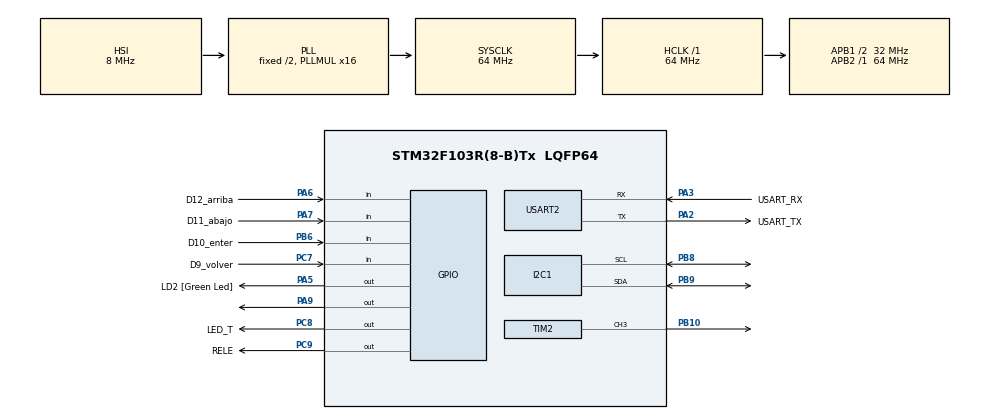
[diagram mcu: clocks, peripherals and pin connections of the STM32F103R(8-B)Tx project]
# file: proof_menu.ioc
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I2C1.I2C_Mode=I2C_Fast
Mcu.Family=STM32F1
Mcu.Name=STM32F103R(8-B)Tx
Mcu.Package=LQFP64
NVIC.PriorityGroup=NVIC_PRIORITYGROUP_4
PA13.GPIO_Label=TMS
PA13.Mode=Serial_Wire
PA13.Signal=SYS_JTMS-SWDIO
PA14.GPIO_Label=TCK
PA14.Mode=Serial_Wire
PA14.Signal=SYS_JTCK-SWCLK
PA2.GPIO_Label=USART_TX
PA2.GPIO_Mode=GPIO_MODE_AF_PP
PA2.GPIO_PuPd=GPIO_NOPULL
PA2.GPIO_Speed=GPIO_SPEED_FREQ_LOW
PA2.Mode=Asynchronous
PA2.Signal=USART2_TX
PA3.GPIO_Label=USART_RX
PA3.GPIO_Mode=GPIO_MODE_AF_PP
PA3.GPIO_PuPd=GPIO_NOPULL
PA3.GPIO_Speed=GPIO_SPEED_FREQ_LOW
PA3.Mode=Asynchronous
PA3.Signal=USART2_RX
PA5.GPIO_Label=LD2 [Green Led]
PA5.GPIO_ModeDefaultOutputPP=GPIO_MODE_OUTPUT_PP
PA5.GPIO_PuPd=GPIO_NOPULL
PA5.GPIO_Speed=GPIO_SPEED_FREQ_LOW
PA5.Signal=GPIO_Output
PA6.GPIO_Label=D12_arriba
PA6.GPIO_PuPd=GPIO_PULLUP
PA6.Signal=GPIO_Input
PA7.GPIO_Label=D11_abajo
PA7.GPIO_PuPd=GPIO_PULLUP
PA7.Signal=GPIO_Input
PA9.Signal=GPIO_Output
PB10.Signal=S_TIM2_CH3
PB3.GPIO_Label=SWO
PB3.Signal=SYS_JTDO-TRACESWO
PB6.GPIO_Label=D10_enter
PB6.GPIO_PuPd=GPIO_PULLUP
PB6.Signal=GPIO_Input
PB8.Mode=I2C
PB8.Signal=I2C1_SCL
PB9.Mode=I2C
PB9.Signal=I2C1_SDA
PC14-OSC32_IN.Mode=LSE-External-Oscillator
PC14-OSC32_IN.Signal=RCC_OSC32_IN
PC15-OSC32_OUT.Mode=LSE-External-Oscillator
PC15-OSC32_OUT.Signal=RCC_OSC32_OUT
PC7.GPIO_Label=D9_volver
PC7.GPIO_PuPd=GPIO_PULLUP
PC7.Signal=GPIO_Input
PC8.GPIO_Label=LED_T
PC8.Signal=GPIO_Output
PC9.GPIO_Label=RELE
PC9.Signal=GPIO_Output
PD0-OSC_IN.Mode=HSE-External-Oscillator
PD0-OSC_IN.Signal=RCC_OSC_IN
PD1-OSC_OUT.Mode=HSE-External-Oscillator
PD1-OSC_OUT.Signal=RCC_OSC_OUT
ProjectManager.HeapSize=0x200
ProjectManager.StackSize=0x400
ProjectManager.TargetToolchain=STM32CubeIDE
RCC.AHBFreq_Value=64000000
RCC.APB1CLKDivider=RCC_HCLK_DIV2
RCC.APB1Freq_Value=32000000
RCC.APB1TimFreq_Value=64000000
RCC.APB2Freq_Value=64000000
RCC.APB2TimFreq_Value=64000000
RCC.HCLKFreq_Value=64000000
RCC.PLLMUL=RCC_PLL_MUL16
RCC.RTCClockSelection=RCC_RTCCLKSOURCE_LSE
RCC.SYSCLKFreq_VALUE=64000000
RCC.SYSCLKSource=RCC_SYSCLKSOURCE_PLLCLK
RCC.USBFreq_Value=64000000
RTC.Format=RTC_FORMAT_BIN
SH.S_TIM2_CH3.0=TIM2_CH3,PWM Generation3 CH3
TIM2.AutoReloadPreload=TIM_AUTORELOAD_PRELOAD_ENABLE
TIM2.Channel-PWM\ Generation3\ CH3=TIM_CHANNEL_3
TIM2.Period=999
TIM2.Prescaler=1279
TIM2.Pulse-PWM\ Generation3\ CH3=50
TIM3.Prescaler=64-1
USART2.VirtualMode=VM_ASYNC
VP_RTC_VS_RTC_Activate.Mode=RTC_Enabled
VP_RTC_VS_RTC_Calendar.Mode=RTC_Calendar
VP_TIM2_VS_ClockSourceINT.Mode=Internal
VP_TIM3_VS_ClockSourceINT.Mode=Internal
board=NUCLEO-F103RB

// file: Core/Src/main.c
/* USER CODE BEGIN Header */
/**
  ******************************************************************************
  * @file           : main.c
  * @brief          : Main program body
  ******************************************************************************
  * @attention
  *
  * Copyright (c) 2026 STMicroelectronics.
  * All rights reserved.
  *
  * This software is licensed under terms that can be found in the LICENSE file
  * in the root directory of this software component.
  * If no LICENSE file comes with this software, it is provided AS-IS.
  *
  ******************************************************************************
  */
/* USER CODE END Header */
#include "main.h"

/* USER CODE BEGIN Includes */

/* Application includes */
#include "logger.h"
#include "app.h"
#include "stm32f1xx_hal.h"
#include "liquidcrystal_i2c.h"

/* USER CODE END Includes */

I2C_HandleTypeDef hi2c1;

RTC_HandleTypeDef hrtc;

TIM_HandleTypeDef htim2;
TIM_HandleTypeDef htim3;

UART_HandleTypeDef huart2;

void SystemClock_Config(void);
static void MX_GPIO_Init(void);
static void MX_USART2_UART_Init(void);
static void MX_I2C1_Init(void);
static void MX_RTC_Init(void);
static void MX_TIM2_Init(void);
static void MX_TIM3_Init(void);

/* USER CODE BEGIN 0 */
#if (1 == LOGGER_CONFIG_USE_SEMIHOSTING)

extern void initialise_monitor_handles(void);

#endif

/* USER CODE END 0 */

int main(void)
{

  /* USER CODE BEGIN 1 */
  #if (1 == LOGGER_CONFIG_USE_SEMIHOSTING)

  initialise_monitor_handles();

  #endif

  /* USER CODE END 1 */

  /* MCU Configuration--------------------------------------------------------*/

  /* Reset of all peripherals, Initializes the Flash interface and the Systick. */
  HAL_Init();

  /* Configure the system clock */
  SystemClock_Config();

  /* Initialize all configured peripherals */
  MX_GPIO_Init();
  MX_USART2_UART_Init();
  MX_I2C1_Init();
  MX_RTC_Init();
  MX_TIM2_Init();
  MX_TIM3_Init();
  /* USER CODE BEGIN 2 */

  HAL_TIM_Base_Start(&htim3);
  /* Application Init */
  app_init();

  /* USER CODE END 2 */

  /* Infinite loop */
  while (1)
  {

    /* USER CODE BEGIN 3 */

    /* Application Update */
    app_update();
  }
  /* USER CODE END 3 */
}

void SystemClock_Config(void)
{
  RCC_OscInitTypeDef RCC_OscInitStruct = {0};
  RCC_ClkInitTypeDef RCC_ClkInitStruct = {0};
  RCC_PeriphCLKInitTypeDef PeriphClkInit = {0};

  /** Initializes the RCC Oscillators according to the specified parameters
  * in the RCC_OscInitTypeDef structure.
  */
  RCC_OscInitStruct.OscillatorType = RCC_OSCILLATORTYPE_HSI|RCC_OSCILLATORTYPE_LSE;
  RCC_OscInitStruct.LSEState = RCC_LSE_ON;
  RCC_OscInitStruct.HSIState = RCC_HSI_ON;
  RCC_OscInitStruct.HSICalibrationValue = RCC_HSICALIBRATION_DEFAULT;
  RCC_OscInitStruct.PLL.PLLState = RCC_PLL_ON;
  RCC_OscInitStruct.PLL.PLLSource = RCC_PLLSOURCE_HSI_DIV2;
  RCC_OscInitStruct.PLL.PLLMUL = RCC_PLL_MUL16;
  if (HAL_RCC_OscConfig(&RCC_OscInitStruct) != HAL_OK)
  {
    Error_Handler();
  }

  /** Initializes the CPU, AHB and APB buses clocks
  */
  RCC_ClkInitStruct.ClockType = RCC_CLOCKTYPE_HCLK|RCC_CLOCKTYPE_SYSCLK
                              |RCC_CLOCKTYPE_PCLK1|RCC_CLOCKTYPE_PCLK2;
  RCC_ClkInitStruct.SYSCLKSource = RCC_SYSCLKSOURCE_PLLCLK;
  RCC_ClkInitStruct.AHBCLKDivider = RCC_SYSCLK_DIV1;
  RCC_ClkInitStruct.APB1CLKDivider = RCC_HCLK_DIV2;
  RCC_ClkInitStruct.APB2CLKDivider = RCC_HCLK_DIV1;

  if (HAL_RCC_ClockConfig(&RCC_ClkInitStruct, FLASH_LATENCY_2) != HAL_OK)
  {
    Error_Handler();
  }
  PeriphClkInit.PeriphClockSelection = RCC_PERIPHCLK_RTC;
  PeriphClkInit.RTCClockSelection = RCC_RTCCLKSOURCE_LSE;
  if (HAL_RCCEx_PeriphCLKConfig(&PeriphClkInit) != HAL_OK)
  {
    Error_Handler();
  }
}

static void MX_I2C1_Init(void)
{

  hi2c1.Instance = I2C1;
  hi2c1.Init.ClockSpeed = 400000;
  hi2c1.Init.DutyCycle = I2C_DUTYCYCLE_2;
  hi2c1.Init.OwnAddress1 = 0;
  hi2c1.Init.AddressingMode = I2C_ADDRESSINGMODE_7BIT;
  hi2c1.Init.DualAddressMode = I2C_DUALADDRESS_DISABLE;
  hi2c1.Init.OwnAddress2 = 0;
  hi2c1.Init.GeneralCallMode = I2C_GENERALCALL_DISABLE;
  hi2c1.Init.NoStretchMode = I2C_NOSTRETCH_DISABLE;
  if (HAL_I2C_Init(&hi2c1) != HAL_OK)
  {
    Error_Handler();
  }

}

static void MX_RTC_Init(void)
{

  RTC_TimeTypeDef sTime = {0};
  RTC_DateTypeDef DateToUpdate = {0};

  /** Initialize RTC Only
  */
  hrtc.Instance = RTC;
  hrtc.Init.AsynchPrediv = RTC_AUTO_1_SECOND;
  hrtc.Init.OutPut = RTC_OUTPUTSOURCE_ALARM;
  if (HAL_RTC_Init(&hrtc) != HAL_OK)
  {
    Error_Handler();
  }

  /** Initialize RTC and set the Time and Date
  */
  sTime.Hours = 0;
  sTime.Minutes = 0;
  sTime.Seconds = 0;

  if (HAL_RTC_SetTime(&hrtc, &sTime, RTC_FORMAT_BIN) != HAL_OK)
  {
    Error_Handler();
  }
  DateToUpdate.WeekDay = RTC_WEEKDAY_MONDAY;
  DateToUpdate.Month = RTC_MONTH_JANUARY;
  DateToUpdate.Date = 1;
  DateToUpdate.Year = 0;

  if (HAL_RTC_SetDate(&hrtc, &DateToUpdate, RTC_FORMAT_BIN) != HAL_OK)
  {
    Error_Handler();
  }

}

static void MX_TIM2_Init(void)
{

  TIM_ClockConfigTypeDef sClockSourceConfig = {0};
  TIM_MasterConfigTypeDef sMasterConfig = {0};
  TIM_OC_InitTypeDef sConfigOC = {0};

  htim2.Instance = TIM2;
  htim2.Init.Prescaler = 1279;
  htim2.Init.CounterMode = TIM_COUNTERMODE_UP;
  htim2.Init.Period = 999;
  htim2.Init.ClockDivision = TIM_CLOCKDIVISION_DIV1;
  htim2.Init.AutoReloadPreload = TIM_AUTORELOAD_PRELOAD_ENABLE;
  if (HAL_TIM_Base_Init(&htim2) != HAL_OK)
  {
    Error_Handler();
  }
  sClockSourceConfig.ClockSource = TIM_CLOCKSOURCE_INTERNAL;
  if (HAL_TIM_ConfigClockSource(&htim2, &sClockSourceConfig) != HAL_OK)
  {
    Error_Handler();
  }
  if (HAL_TIM_PWM_Init(&htim2) != HAL_OK)
  {
    Error_Handler();
  }
  sMasterConfig.MasterOutputTrigger = TIM_TRGO_RESET;
  sMasterConfig.MasterSlaveMode = TIM_MASTERSLAVEMODE_DISABLE;
  if (HAL_TIMEx_MasterConfigSynchronization(&htim2, &sMasterConfig) != HAL_OK)
  {
    Error_Handler();
  }
  sConfigOC.OCMode = TIM_OCMODE_PWM1;
  sConfigOC.Pulse = 50;
  sConfigOC.OCPolarity = TIM_OCPOLARITY_HIGH;
  sConfigOC.OCFastMode = TIM_OCFAST_DISABLE;
  if (HAL_TIM_PWM_ConfigChannel(&htim2, &sConfigOC, TIM_CHANNEL_3) != HAL_OK)
  {
    Error_Handler();
  }
  HAL_TIM_MspPostInit(&htim2);

}

static void MX_TIM3_Init(void)
{

  TIM_ClockConfigTypeDef sClockSourceConfig = {0};
  TIM_MasterConfigTypeDef sMasterConfig = {0};

  htim3.Instance = TIM3;
  htim3.Init.Prescaler = 64-1;
  htim3.Init.CounterMode = TIM_COUNTERMODE_UP;
  htim3.Init.Period = 65535;
  htim3.Init.ClockDivision = TIM_CLOCKDIVISION_DIV1;
  htim3.Init.AutoReloadPreload = TIM_AUTORELOAD_PRELOAD_DISABLE;
  if (HAL_TIM_Base_Init(&htim3) != HAL_OK)
  {
    Error_Handler();
  }
  sClockSourceConfig.ClockSource = TIM_CLOCKSOURCE_INTERNAL;
  if (HAL_TIM_ConfigClockSource(&htim3, &sClockSourceConfig) != HAL_OK)
  {
    Error_Handler();
  }
  sMasterConfig.MasterOutputTrigger = TIM_TRGO_RESET;
  sMasterConfig.MasterSlaveMode = TIM_MASTERSLAVEMODE_DISABLE;
  if (HAL_TIMEx_MasterConfigSynchronization(&htim3, &sMasterConfig) != HAL_OK)
  {
    Error_Handler();
  }

}

static void MX_USART2_UART_Init(void)
{

  huart2.Instance = USART2;
  huart2.Init.BaudRate = 115200;
  huart2.Init.WordLength = UART_WORDLENGTH_8B;
  huart2.Init.StopBits = UART_STOPBITS_1;
  huart2.Init.Parity = UART_PARITY_NONE;
  huart2.Init.Mode = UART_MODE_TX_RX;
  huart2.Init.HwFlowCtl = UART_HWCONTROL_NONE;
  huart2.Init.OverSampling = UART_OVERSAMPLING_16;
  if (HAL_UART_Init(&huart2) != HAL_OK)
  {
    Error_Handler();
  }

}

static void MX_GPIO_Init(void)
{
  GPIO_InitTypeDef GPIO_InitStruct = {0};

  /* GPIO Ports Clock Enable */
  __HAL_RCC_GPIOC_CLK_ENABLE();
  __HAL_RCC_GPIOD_CLK_ENABLE();
  __HAL_RCC_GPIOA_CLK_ENABLE();
  __HAL_RCC_GPIOB_CLK_ENABLE();

  /*Configure GPIO pin Output Level */
  HAL_GPIO_WritePin(GPIOA, LD2_Pin|GPIO_PIN_9, GPIO_PIN_RESET);

  /*Configure GPIO pin Output Level */
  HAL_GPIO_WritePin(GPIOC, LED_T_Pin|RELE_Pin, GPIO_PIN_RESET);

  /*Configure GPIO pins : LD2_Pin PA9 */
  GPIO_InitStruct.Pin = LD2_Pin|GPIO_PIN_9;
  GPIO_InitStruct.Mode = GPIO_MODE_OUTPUT_PP;
  GPIO_InitStruct.Pull = GPIO_NOPULL;
  GPIO_InitStruct.Speed = GPIO_SPEED_FREQ_LOW;
  HAL_GPIO_Init(GPIOA, &GPIO_InitStruct);

  /*Configure GPIO pins : D12_arriba_Pin D11_abajo_Pin */
  GPIO_InitStruct.Pin = D12_arriba_Pin|D11_abajo_Pin;
  GPIO_InitStruct.Mode = GPIO_MODE_INPUT;
  GPIO_InitStruct.Pull = GPIO_PULLUP;
  HAL_GPIO_Init(GPIOA, &GPIO_InitStruct);

  /*Configure GPIO pin : D9_volver_Pin */
  GPIO_InitStruct.Pin = D9_volver_Pin;
  GPIO_InitStruct.Mode = GPIO_MODE_INPUT;
  GPIO_InitStruct.Pull = GPIO_PULLUP;
  HAL_GPIO_Init(D9_volver_GPIO_Port, &GPIO_InitStruct);

  /*Configure GPIO pins : LED_T_Pin RELE_Pin */
  GPIO_InitStruct.Pin = LED_T_Pin|RELE_Pin;
  GPIO_InitStruct.Mode = GPIO_MODE_OUTPUT_PP;
  GPIO_InitStruct.Pull = GPIO_NOPULL;
  GPIO_InitStruct.Speed = GPIO_SPEED_FREQ_LOW;
  HAL_GPIO_Init(GPIOC, &GPIO_InitStruct);

  /*Configure GPIO pin : D10_enter_Pin */
  GPIO_InitStruct.Pin = D10_enter_Pin;
  GPIO_InitStruct.Mode = GPIO_MODE_INPUT;
  GPIO_InitStruct.Pull = GPIO_PULLUP;
  HAL_GPIO_Init(D10_enter_GPIO_Port, &GPIO_InitStruct);

}

void Error_Handler(void)
{
  __disable_irq();
  while (1)
  {
  }
}
